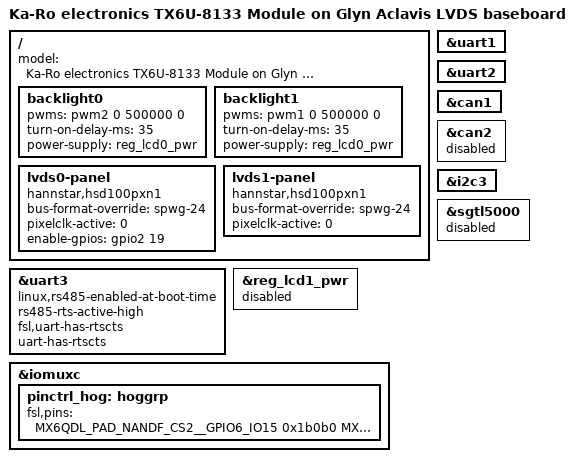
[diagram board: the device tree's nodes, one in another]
/*
 * Copyright 2019 ./kernel concepts <florian@kernelconcepts.de>
 *
 *
 * This file is free software; you can redistribute it and/or
 * modify it under the terms of the GNU General Public License
 * version 2 as published by the Free Software Foundation.
 * 
 * This file is distributed in the hope that it will be useful,
 * but WITHOUT ANY WARRANTY; without even the implied warranty of
 * MERCHANTABILITY or FITNESS FOR A PARTICULAR PURPOSE.  See the
 * GNU General Public License for more details.
 *
 */

/dts-v1/;
#include "imx6dl-tx6u-8133.dts"

/ {
	model = "Ka-Ro electronics TX6U-8133 Module on Glyn Aclavis LVDS baseboard";

	backlight0 {
		pwms = <&pwm2 0 500000 0>;
		turn-on-delay-ms = <35>;
		power-supply = <&reg_lcd0_pwr>;
	};

	backlight1: backlight1 {
	    pwms = <&pwm1 0 500000 0>;
	    turn-on-delay-ms = <35>;
		power-supply = <&reg_lcd0_pwr>;
	};

	lvds0-panel {
		compatible = "hannstar,hsd100pxn1";
		bus-format-override = "spwg-24";
		pixelclk-active = <0>;
		enable-gpios = <&gpio2 19 GPIO_ACTIVE_HIGH>; // TX Pin 154
	};
	
	lvds1-panel {
		compatible = "hannstar,hsd100pxn1";
		bus-format-override = "spwg-24";
		pixelclk-active = <0>;
	};	

	/delete-node/ sound;
};

&uart1 {
	status = "okay";
};

&uart2 {
	status = "okay";
	dma-names = "","";
	/delete-property/ uart-has-rtscts;
	/delete-property/ fsl,uart-has-rtscts;
};

&uart3 {
	status = "okay";
	dma-names = "","";

//    /* RS485 */
    linux,rs485-enabled-at-boot-time;
//    rs485-rts-delay = <0 0>;
	rs485-rts-active-high; // unused, future kernel			 
	fsl,uart-has-rtscts;	
	uart-has-rtscts;	
};

&can1 {
	status = "okay";
};

&can2 {
	status = "disabled";
};

&i2c3 {
    /delete-node/ edt-ft5x06@38;
};

&sgtl5000 {
	status = "disabled";
};

&reg_lcd1_pwr {
	status = "disabled";
};

&iomuxc {
	pinctrl_hog: hoggrp {
		fsl,pins = <
			MX6QDL_PAD_NANDF_CS2__GPIO6_IO15    0x1b0b0 /* Pin 148: OPTO IN */
			MX6QDL_PAD_EIM_A16__GPIO2_IO22      0x1b0b0	/* Pin 149: OPTO IN */
			MX6QDL_PAD_EIM_EB3__GPIO2_IO31      0x1b0b0 /* Pin 151: OPTO OUT */
			MX6QDL_PAD_EIM_A17__GPIO2_IO21      0x1b0b0 /* Pin 152: OPTO OUT */
			MX6QDL_PAD_EIM_A19__GPIO2_IO19      0x1b0b0 /* Pin 154: Backlight enable */
			MX6QDL_PAD_EIM_DA6__GPIO3_IO06      0x1b0b0 /* Pin 190: for debugging */
		>;
	};
};
